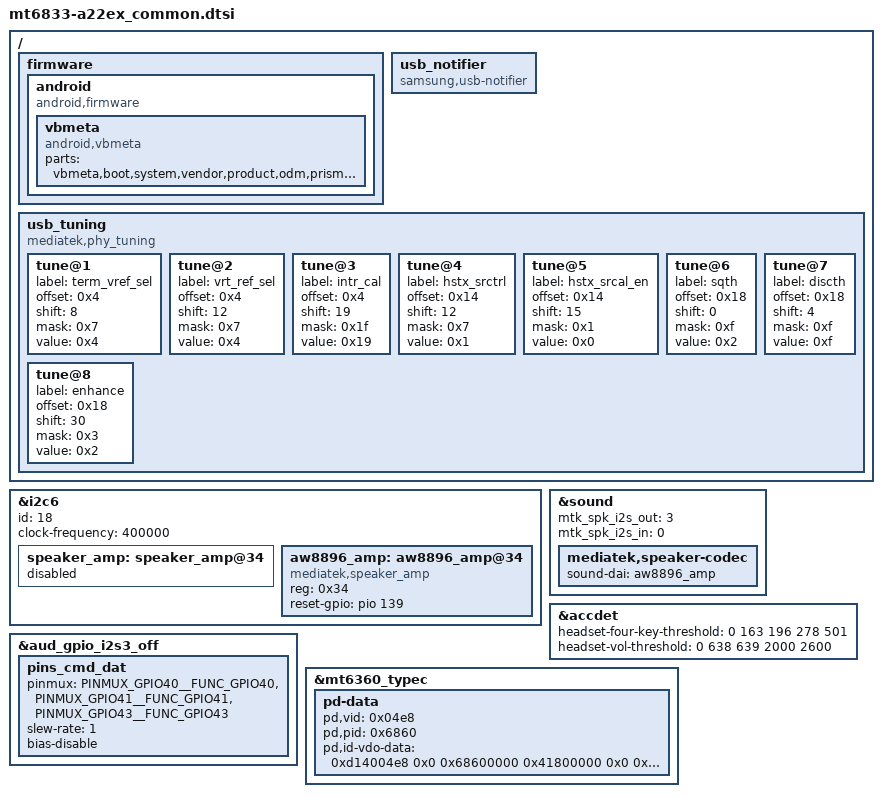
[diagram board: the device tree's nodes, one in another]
/* Generated by Samsung for MTK vendor board
 * If these files should be changed, then please make a sync with MTK
*/

#include "display_lcd_a22ex_common.dtsi"

/* Add Samsung configuration over here */
/ {
	fragment@model {
		target-path = "/";
		__overlay__ {
			firmware {
				android {
					compatible = "android,firmware";
					vbmeta {
						compatible = "android,vbmeta";
						parts = "vbmeta,boot,system,vendor,product,odm,prism,optics,vbmeta_system,recovery,lk,tee1";
					};
				};
			};
			usb_notifier {
				compatible = "samsung,usb-notifier";
			};

			usb_tuning: usb_tuning {
				compatible = "mediatek,phy_tuning";

				tune@1 {
					label = "term_vref_sel";
					offset = <0x4>;
					shift = <8>;
					mask = <0x7>;
					value = <0x4>;
				};
				tune@2 {
					label = "vrt_ref_sel";
					offset = <0x4>;
					shift = <12>;
					mask = <0x7>;
					value = <0x4>;
				};
				tune@3 {
					label = "intr_cal";
					offset = <0x4>;
					shift = <19>;
					mask = <0x1f>;
					value = <0x19>;
				};
				tune@4 {
					label = "hstx_srctrl";
					offset = <0x14>;
					shift = <12>;
					mask = <0x7>;
					value = <0x1>;
				};
				tune@5 {
					label = "hstx_srcal_en";
					offset = <0x14>;
					shift = <15>;
					mask = <0x1>;
					value = <0x0>;
				};
				tune@6 {
					label = "sqth";
					offset = <0x18>;
					shift = <0>;
					mask = <0xf>;
					value = <0x2>;
				};
				tune@7 {
					label = "discth";
					offset = <0x18>;
					shift = <4>;
					mask = <0xf>;
					value = <0xf>;
				};
				tune@8 {
					label = "enhance";
					offset = <0x18>;
					shift = <30>;
					mask = <0x3>;
					value = <0x2>;
				};
			};
		};
	};
};

&i2c6 {
	speaker_amp: speaker_amp@34 {
		status = "disabled";
	};
};

&i2c6 {
	status = "okay";
	id = <18>;
	clock-frequency = <400000>;
	#address-cells = <1>;
	#size-cells = <0>;

	aw8896_amp: aw8896_amp@34 {
		compatible = "mediatek,speaker_amp";
		#sound-dai-cells = <0>;
		reg = <0x34>;
		reset-gpio = <&pio 139 0>;
		status = "okay";
	};
};

&sound {
	mtk_spk_i2s_out = <3>;
	mtk_spk_i2s_in = <0>;
	mediatek,speaker-codec {
		sound-dai = <&aw8896_amp>;
	};
};

/* accdet start */
&accdet {
	headset-four-key-threshold = <0 163 196 278 501>;
	headset-vol-threshold = <0 638 639 2000 2600>;
};
/* accdet end */

/* I2S gpio configuration */
&aud_gpio_i2s3_off {
	pins_cmd_dat {
		pinmux = <PINMUX_GPIO40__FUNC_GPIO40>,
			 <PINMUX_GPIO41__FUNC_GPIO41>,
			 <PINMUX_GPIO43__FUNC_GPIO43>;
		slew-rate = <1>;
		bias-disable;
	};
};

&mt6360_typec {
	pd-data {
		pd,vid = <0x04e8>;
		pd,pid = <0x6860>;
		pd,id-vdo-data = <0xd14004e8 0x0 0x68600000
				 0x41800000 0x0 0x21800000>;
	};
};
